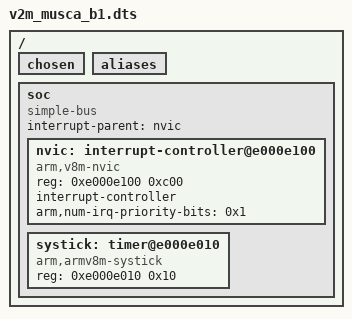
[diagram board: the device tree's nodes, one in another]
/dts-v1/;

/ {
	#address-cells = < 0x1 >;
	#size-cells = < 0x1 >;
	chosen {
	};
	aliases {
	};
	soc {
		#address-cells = < 0x1 >;
		#size-cells = < 0x1 >;
		compatible = "simple-bus";
		interrupt-parent = < &nvic >;
		ranges;
		nvic: interrupt-controller@e000e100 {
			#address-cells = < 0x1 >;
			compatible = "arm,v8m-nvic";
			reg = < 0xe000e100 0xc00 >;
			interrupt-controller;
			#interrupt-cells = < 0x2 >;
			arm,num-irq-priority-bits = < 0x1 >;
			phandle = < 0x1 >;
		};
		systick: timer@e000e010 {
			compatible = "arm,armv8m-systick";
			reg = < 0xe000e010 0x10 >;
		};
	};
};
